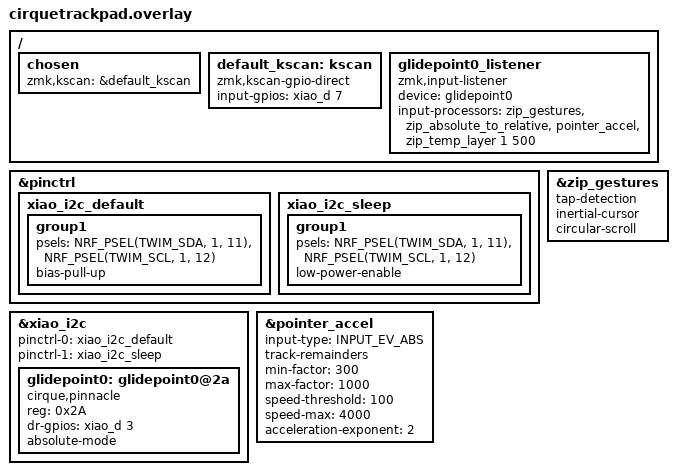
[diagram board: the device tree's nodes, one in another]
// cirquetrackpad.overlay
#include <dt-bindings/zmk/matrix_transform.h>
#include <physical_layouts.dtsi>
#include <input/processors.dtsi>
#include <dt-bindings/zmk/input_transform.h>
#include <behaviors/input_gestures_accel.dtsi>
#include <behaviors/input_processor_gestures.dtsi>
#include <behaviors/input_processor_absolute_to_relative.dtsi>
#include <zephyr/dt-bindings/input/input-event-codes.h>

/ {
    chosen {
        //zmk,physical-layout = &physical_layout0;
        zmk,kscan = &default_kscan;
    };

    default_kscan: kscan {
        compatible = "zmk,kscan-gpio-direct";
        input-gpios
            = <&xiao_d 7 (GPIO_ACTIVE_HIGH | GPIO_PULL_DOWN)> // Row A from the schematic file
            ;
    };
};

&pinctrl {
    xiao_i2c_default: xiao_i2c_default {
        group1 {
            psels = <NRF_PSEL(TWIM_SDA, 1, 11)>, <NRF_PSEL(TWIM_SCL, 1, 12)>;
            bias-pull-up;
        };
    };
    xiao_i2c_sleep: xiao_i2c_sleep {
        group1 {
            psels = <NRF_PSEL(TWIM_SDA, 1, 11)>, <NRF_PSEL(TWIM_SCL, 1, 12)>;
            low-power-enable;
        };
    };
};

&xiao_i2c {
    status = "okay";
    pinctrl-0 = <&xiao_i2c_default>;
    pinctrl-1 = <&xiao_i2c_sleep>;
    pinctrl-names = "default", "sleep";

    glidepoint0: glidepoint0@2a {
        compatible = "cirque,pinnacle";
        reg = <0x2A>;    
        status = "okay";
        dr-gpios = <&xiao_d 3 (GPIO_ACTIVE_HIGH)>;

        absolute-mode;
    };
};

&zip_gestures {
    // https://github.com/halfdane/zmk-input-gestures

    // Activate gestures and change their configuration as you see fit.
    // for details, see the section below that describes all gestures and
    // their configuration options.

    // This will create a mouseclick if your touch is short enough.
    // if you're running in relative mode and don't use no-taps, this might
    // result in duplicate taps

    tap-detection;
    inertial-cursor;
    circular-scroll;
};

&pointer_accel {
    // https://github.com/oleksandrmaslov/zmk-pointing-acceleration
    
    input-type = <INPUT_EV_ABS>;  // For relative input devices
    track-remainders;             // Accumulate fractional movements
    min-factor = <300>;          // 0.8x at very slow speeds
    max-factor = <1000>;         // 3.0x at fast speeds
    speed-threshold = <100>;     // counts/sec for 1x
    speed-max = <4000>;          // 6000 counts/sec for max accel
    acceleration-exponent = <2>;  // Quadratic acceleration curve
};

/ {
    glidepoint0_listener: glidepoint0_listener {
        compatible = "zmk,input-listener";
        status = "okay";
        device = <&glidepoint0>;
        input-processors = <
            &zip_gestures
            &zip_absolute_to_relative
            &pointer_accel
            &zip_temp_layer 1 500
	    >;

    };

};
